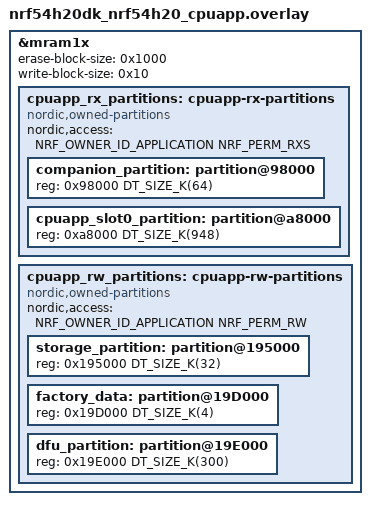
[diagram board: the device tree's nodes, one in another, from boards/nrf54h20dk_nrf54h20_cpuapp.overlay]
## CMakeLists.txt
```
#
# Copyright (c) 2023 Nordic Semiconductor ASA
#
# SPDX-License-Identifier: LicenseRef-Nordic-5-Clause
#

cmake_minimum_required(VERSION 3.20.0)

find_package(Zephyr HINTS $ENV{ZEPHYR_BASE})

project(matter-bridge)

# Enable GNU STD support and initialize the Matter Data Model.
include(${ZEPHYR_CONNECTEDHOMEIP_MODULE_DIR}/config/nrfconnect/app/enable-gnu-std.cmake)
include(${ZEPHYR_CONNECTEDHOMEIP_MODULE_DIR}/src/app/chip_data_model.cmake)

# NORDIC SDK APP START

# Include all source files that are located in the Matter common directory.
include(${ZEPHYR_NRF_MODULE_DIR}/samples/matter/common/cmake/source_common.cmake)

target_include_directories(app PRIVATE
    src
    src/bridged_device_types
    ${CONFIG_NCS_SAMPLE_MATTER_ZAP_FILES_PATH}
    ${ZEPHYR_NRF_MODULE_DIR}/samples/matter/common/src/bridge/
    ${ZEPHYR_NRF_MODULE_DIR}/samples/matter/common/src/bridge/util
)

target_sources(app PRIVATE
    src/app_task.cpp
    src/main.cpp
    src/bridge_shell.cpp
    src/zcl_callbacks.cpp
    ${ZEPHYR_NRF_MODULE_DIR}/samples/matter/common/src/bridge/bridge_manager.cpp
    ${ZEPHYR_NRF_MODULE_DIR}/samples/matter/common/src/bridge/matter_bridged_device.cpp
    ${ZEPHYR_NRF_MODULE_DIR}/samples/matter/common/src/bridge/bridge_storage_manager.cpp
    ${ZEPHYR_NRF_MODULE_DIR}/samples/matter/common/src/bridge/bridged_device_data_provider.cpp
    ${ZEPHYR_NRF_MODULE_DIR}/samples/matter/common/src/binding/binding_handler.cpp
)

if(CONFIG_BRIDGED_DEVICE_BT)
    target_sources(app PRIVATE
         ${ZEPHYR_NRF_MODULE_DIR}/samples/matter/common/src/bridge/ble_connectivity_manager.cpp
        src/ble_providers/ble_bridged_device_factory.cpp
    )
    target_include_directories(app PRIVATE src/ble_providers)

if(CONFIG_BRIDGE_ONOFF_LIGHT_BRIDGED_DEVICE AND (CONFIG_BRIDGE_GENERIC_SWITCH_BRIDGED_DEVICE OR CONFIG_BRIDGE_ONOFF_LIGHT_SWITCH_BRIDGED_DEVICE))
    target_sources(app PRIVATE
        src/bridged_device_types/onoff_light.cpp
        src/ble_providers/ble_lbs_data_provider.cpp
    )

if(CONFIG_BRIDGE_GENERIC_SWITCH_BRIDGED_DEVICE)
    target_sources(app PRIVATE src/bridged_device_types/generic_switch.cpp)
endif()

if(CONFIG_BRIDGE_ONOFF_LIGHT_SWITCH_BRIDGED_DEVICE)
    target_sources(app PRIVATE
        src/bridged_device_types/onoff_light_switch.cpp
    )
endif()

endif() # CONFIG_BRIDGE_ONOFF_LIGHT_BRIDGED_DEVICE AND (CONFIG_BRIDGE_GENERIC_SWITCH_BRIDGED_DEVICE OR CONFIG_BRIDGE_ONOFF_LIGHT_SWITCH_BRIDGED_DEVICE)

if(CONFIG_BRIDGE_HUMIDITY_SENSOR_BRIDGED_DEVICE)
    target_sources(app PRIVATE
        src/bridged_device_types/humidity_sensor.cpp
    )
endif() # CONFIG_BRIDGE_HUMIDITY_SENSOR_BRIDGED_DEVICE

if(CONFIG_BRIDGE_TEMPERATURE_SENSOR_BRIDGED_DEVICE)
    target_sources(app PRIVATE
        src/bridged_device_types/temperature_sensor.cpp
    )
endif() # CONFIG_BRIDGE_TEMPERATURE_SENSOR_BRIDGED_DEVICE

# Assume it makes no sense to support BLE environmental sensor without all Matter counterparts
if(CONFIG_BRIDGE_TEMPERATURE_SENSOR_BRIDGED_DEVICE AND CONFIG_BRIDGE_HUMIDITY_SENSOR_BRIDGED_DEVICE)
    target_sources(app PRIVATE
        src/ble_providers/ble_environmental_data_provider.cpp
    )
endif() # CONFIG_BRIDGE_TEMPERATURE_SENSOR_BRIDGED_DEVICE AND CONFIG_BRIDGE_HUMIDITY_SENSOR_BRIDGED_DEVICE

else()
    target_sources(app PRIVATE
        src/simulated_providers/simulated_bridged_device_factory.cpp
    )
    target_include_directories(app PRIVATE src/simulated_providers)

if(CONFIG_BRIDGE_ONOFF_LIGHT_BRIDGED_DEVICE AND (CONFIG_BRIDGE_GENERIC_SWITCH_BRIDGED_DEVICE OR CONFIG_BRIDGE_ONOFF_LIGHT_SWITCH_BRIDGED_DEVICE))
    target_sources(app PRIVATE
        src/bridged_device_types/onoff_light.cpp
        src/simulated_providers/simulated_onoff_light_data_provider.cpp
    )

if(CONFIG_BRIDGE_GENERIC_SWITCH_BRIDGED_DEVICE)
    target_sources(app PRIVATE
        src/bridged_device_types/generic_switch.cpp
        src/simulated_providers/simulated_generic_switch_data_provider.cpp
    )
endif()

if(CONFIG_BRIDGE_ONOFF_LIGHT_SWITCH_BRIDGED_DEVICE)
    target_sources(app PRIVATE
        src/bridged_device_types/onoff_light_switch.cpp
        src/simulated_providers/simulated_onoff_light_switch_data_provider.cpp
    )
endif()

endif() # CONFIG_BRIDGE_ONOFF_LIGHT_BRIDGED_DEVICE AND (CONFIG_BRIDGE_GENERIC_SWITCH_BRIDGED_DEVICE OR CONFIG_BRIDGE_ONOFF_LIGHT_SWITCH_BRIDGED_DEVICE))

if(CONFIG_BRIDGE_TEMPERATURE_SENSOR_BRIDGED_DEVICE)
    target_sources(app PRIVATE
            src/bridged_device_types/temperature_sensor.cpp
            src/simulated_providers/simulated_temperature_sensor_data_provider.cpp
    )
endif() # CONFIG_BRIDGE_TEMPERATURE_SENSOR_BRIDGED_DEVICE

if(CONFIG_BRIDGE_HUMIDITY_SENSOR_BRIDGED_DEVICE)
    target_sources(app PRIVATE
        src/bridged_device_types/humidity_sensor.cpp
        src/simulated_providers/simulated_humidity_sensor_data_provider.cpp
    )
endif() # CONFIG_BRIDGE_HUMIDITY_SENSOR_BRIDGED_DEVICE

endif() # CONFIG_BRIDGED_DEVICE_BT

chip_configure_data_model(app
    INCLUDE_SERVER
    BYPASS_IDL
    GEN_DIR ${CONFIG_NCS_SAMPLE_MATTER_ZAP_FILES_PATH}/zap-generated
    ZAP_FILE ${CMAKE_CURRENT_SOURCE_DIR}/${CONFIG_NCS_SAMPLE_MATTER_ZAP_FILES_PATH}/bridge.zap
)
# NORDIC SDK APP END
```

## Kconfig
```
#
# Copyright (c) 2023 Nordic Semiconductor
#
# SPDX-License-Identifier: LicenseRef-Nordic-5-Clause
#
mainmenu "Matter nRF Connect Bridge Example Application"

config BRIDGE_ONOFF_LIGHT_BRIDGED_DEVICE
	bool "Support for OnOff Light bridged device"
	default y

config BRIDGE_TEMPERATURE_SENSOR_BRIDGED_DEVICE
	bool "Support for Temperature Sensor bridged device"
	default y

config BRIDGE_HUMIDITY_SENSOR_BRIDGED_DEVICE
	bool "Support for Humidity Sensor bridged device"
	default y

choice BRIDGE_SWITCH_BRIDGED_DEVICE
	prompt "Bridged device switch implementation"
	default BRIDGE_GENERIC_SWITCH_BRIDGED_DEVICE

config BRIDGE_GENERIC_SWITCH_BRIDGED_DEVICE
	bool "Support for Generic Switch bridged device"

config BRIDGE_ONOFF_LIGHT_SWITCH_BRIDGED_DEVICE
	bool "Support for OnOff Light Switch bridged device"

endchoice

choice BRIDGED_DEVICE_IMPLEMENTATION
	prompt "Bridged Device implementation"
	default BRIDGED_DEVICE_SIMULATED

	config BRIDGED_DEVICE_SIMULATED
		bool "Simulated Bridged Device"
		help
		  Enables using simulated bridged devices that do not perform
		  real operations, but emulate exemplary data to imitate the real
		  device behavior.

	config BRIDGED_DEVICE_BT
		bool "Bluetooth LE Bridged Device"
		help
		  Enables using real bridged devices that communicate with the Matter bridge device
		  over Bluetooth LE.

endchoice

if BRIDGED_DEVICE_SIMULATED

choice BRIDGED_DEVICE_SIMULATED_ONOFF_IMPLEMENTATION
	prompt "Simulated bridged onoff device implementation"
	default BRIDGED_DEVICE_SIMULATED_ONOFF_SHELL

	config BRIDGED_DEVICE_SIMULATED_ONOFF_AUTOMATIC
		bool "Automatically simulated bridged onoff device"
		help
		  Enables using simulated bridged onoff device that
		  automatically changes its state periodically.

	config BRIDGED_DEVICE_SIMULATED_ONOFF_SHELL
		bool "Shell controlled simulated bridged onoff device"
		help
		  Enables using simulated bridged onoff device that is
		  controlled by shell commands.

endchoice

endif

if BRIDGED_DEVICE_BT

config BT_CENTRAL
	default y

config BT_SCAN
	default y

# Configure how many Bluetooth LE devices the Matter bridge can support (the final number is given value - 1, as 1 connection is used for the Matter Bluetooth LE service).
config BT_MAX_CONN
	default 10

# Set ACL RX count to CONFIG_BT_MAX_CONN + 1, as it is expected that CONFIG_BT_BUF_ACL_RX_COUNT > CONFIG_BT_MAX_CONN.
config BT_BUF_ACL_RX_COUNT
	default 11

config BT_SCAN_FILTER_ENABLE
	default y

# Configure how many Bluetooth LE service UUIDs the Matter bridge can scan.
config BT_SCAN_UUID_CNT
	default 2

config BT_SCAN_ADDRESS_CNT
	default 1

config BT_GATT_CLIENT
	default y

config BT_GATT_DM
	default y

config BT_EXT_ADV
	default y

config BT_SMP
	default y

if BT_SMP

config BT_SETTINGS
	default y

# Configure how many Bluetooth LE devices will be paired with Matter bridge. Assuming it will be only bridged devices, it should be set to BT_MAX_CONN - 1.
config BT_MAX_PAIRED
	default 9

# Use two Bluetooth LE identities. The first one is used by the peripheral for Matter service advertising purposes, and the other is used by the Matter bridge central.
config BT_ID_MAX
	default 2

config BT_EXT_ADV_LEGACY_SUPPORT
	default y

endif

config BRIDGE_BLE_DEVICE_POLLING_INTERVAL
	int "BLE humidity measurement readout polling interval in ms"
	default 3000

endif

if BRIDGE_TEMPERATURE_SENSOR_BRIDGED_DEVICE

config BRIDGE_TEMPERATURE_SENSOR_MIN_MEASURED_VALUE
	int "Default minimum measured value allowed by the bridged temperature sensor device"
	default -20

config BRIDGE_TEMPERATURE_SENSOR_MAX_MEASURED_VALUE
	int "Default maximum measured value allowed by the bridged temperature sensor device"
	default 60

endif

if BRIDGE_HUMIDITY_SENSOR_BRIDGED_DEVICE

config BRIDGE_HUMIDITY_SENSOR_MIN_MEASURED_VALUE
	int "Default minimum measured value allowed by the bridged humidity sensor device"
	default 0

config BRIDGE_HUMIDITY_SENSOR_MAX_MEASURED_VALUE
	int "Default maximum measured value allowed by the bridged humidity sensor device"
	default 100

endif

# Enable Read Client functionality for all build configurations.
config CHIP_ENABLE_READ_CLIENT
	default y

config NCS_SAMPLE_MATTER_PERSISTENT_STORAGE
	default y

config BRIDGE_SMART_PLUG_SUPPORT
	bool "Enables additional endpoint implementing Matter smart plug functionality"
	default n

# Sample configuration used for Thread networking
if NET_L2_OPENTHREAD

choice OPENTHREAD_NORDIC_LIBRARY_CONFIGURATION
	default OPENTHREAD_NORDIC_LIBRARY_FTD
endchoice

choice OPENTHREAD_DEVICE_TYPE
	default OPENTHREAD_FTD
endchoice

endif # NET_L2_OPENTHREAD

# Dummy Kconfig just to select experimental for some of the configurations.
config BRIDGE_EXPERIMENTAL
	bool
	default y if NET_L2_OPENTHREAD || BRIDGE_SMART_PLUG_SUPPORT
	select EXPERIMENTAL

source "${ZEPHYR_CONNECTEDHOMEIP_MODULE_DIR}/config/nrfconnect/chip-module/Kconfig.features"
source "${ZEPHYR_CONNECTEDHOMEIP_MODULE_DIR}/config/nrfconnect/chip-module/Kconfig.defaults"
source "${ZEPHYR_NRF_MODULE_DIR}/samples/matter/common/src/bridge/Kconfig"
source "${ZEPHYR_NRF_MODULE_DIR}/samples/matter/common/src/Kconfig"
source "Kconfig.zephyr"
```

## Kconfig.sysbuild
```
#
# Copyright (c) 2023 Nordic Semiconductor ASA
#
# SPDX-License-Identifier: LicenseRef-Nordic-5-Clause
#

config WIFI_NRF70
	default y if BOARD_NRF7002DK

#### Radio core
config NRF_DEFAULT_IPC_RADIO
	default y

# Enable Bluetooth serialization to network core
config NETCORE_IPC_RADIO_BT_HCI_IPC
	default y

#### Bootloader
choice BOOTLOADER
	default BOOTLOADER_MCUBOOT if !SOC_SERIES_NRF54HX
endchoice

# Enable IEEE802.15.4 serialization to network core
# This config automatically pulls in the `overlay-802154.conf` in the ipc_radio image
config NETCORE_IPC_RADIO_IEEE802154
	default y if (SOC_SERIES_NRF53X || SOC_SERIES_NRF54HX) && !WIFI_NRF70

if BOOTLOADER_MCUBOOT

#### DFU multi-image support
config DFU_MULTI_IMAGE_PACKAGE_BUILD
	default y

config DFU_MULTI_IMAGE_PACKAGE_APP
	default y

config PM_EXTERNAL_FLASH_MCUBOOT_SECONDARY
	default y

#### DFU network core configuration
if SOC_SERIES_NRF53X

config MCUBOOT_UPDATEABLE_IMAGES
	default 3 if (BOARD_NRF5340DK_NRF5340_CPUAPP && WIFI_NRF70) #### Support for WiFi patch on external flash memory.
	default 2

choice MCUBOOT_MODE
	default MCUBOOT_MODE_OVERWRITE_ONLY
endchoice

choice BOOT_SIGNATURE_TYPE
	default BOOT_SIGNATURE_TYPE_RSA
endchoice

config SECURE_BOOT_NETCORE
	default y

config NETCORE_APP_UPDATE
	default y

config DFU_MULTI_IMAGE_PACKAGE_NET
	default y

endif # SOC_SERIES_NRF53X
endif # BOOTLOADER_MCUBOOT

## Disable DFU for nRF54h20
config MATTER_OTA
	default n if SOC_SERIES_NRF54HX

#### Enable generating factory data
config MATTER_FACTORY_DATA_GENERATE
	default y

source "${ZEPHYR_BASE}/share/sysbuild/Kconfig"
```

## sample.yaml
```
sample:
  description: Matter Bridge
  name: Matter Bridge application
tests:
  applications.matter_bridge.release:
    sysbuild: true
    build_only: true
    extra_args: FILE_SUFFIX=release
      CONFIG_BRIDGE_GENERIC_SWITCH_BRIDGED_DEVICE=n
      CONFIG_BRIDGE_ONOFF_LIGHT_SWITCH_BRIDGED_DEVICE=y
    integration_platforms:
      - nrf7002dk/nrf5340/cpuapp
      - nrf5340dk/nrf5340/cpuapp
      - nrf54h20dk/nrf54h20/cpuapp
    platform_allow: nrf7002dk/nrf5340/cpuapp nrf5340dk/nrf5340/cpuapp
      nrf54h20dk/nrf54h20/cpuapp
    tags: sysbuild ci_applications_matter
  applications.matter_bridge.lto:
    sysbuild: true
    build_only: true
    extra_args: CONFIG_BRIDGE_GENERIC_SWITCH_BRIDGED_DEVICE=n
      CONFIG_BRIDGE_ONOFF_LIGHT_SWITCH_BRIDGED_DEVICE=y
    integration_platforms:
      - nrf7002dk/nrf5340/cpuapp
      - nrf5340dk/nrf5340/cpuapp
      - nrf54h20dk/nrf54h20/cpuapp
    platform_allow: nrf7002dk/nrf5340/cpuapp nrf5340dk/nrf5340/cpuapp
      nrf54h20dk/nrf54h20/cpuapp
    tags: sysbuild ci_applications_matter
  applications.matter_bridge.lto.br_ble:
    sysbuild: true
    build_only: true
    extra_args: CONFIG_BRIDGED_DEVICE_BT=y
      CONFIG_BRIDGE_GENERIC_SWITCH_BRIDGED_DEVICE=n
      CONFIG_BRIDGE_ONOFF_LIGHT_SWITCH_BRIDGED_DEVICE=y
    integration_platforms:
      - nrf7002dk/nrf5340/cpuapp
      - nrf5340dk/nrf5340/cpuapp
      - nrf54h20dk/nrf54h20/cpuapp
    platform_allow: nrf7002dk/nrf5340/cpuapp nrf5340dk/nrf5340/cpuapp
      nrf54h20dk/nrf54h20/cpuapp
    tags: sysbuild ci_applications_matter
  applications.matter_bridge.release.br_ble:
    sysbuild: true
    build_only: true
    extra_args: FILE_SUFFIX=release CONFIG_BRIDGED_DEVICE_BT=y
      CONFIG_BRIDGE_GENERIC_SWITCH_BRIDGED_DEVICE=n
      CONFIG_BRIDGE_ONOFF_LIGHT_SWITCH_BRIDGED_DEVICE=y
    integration_platforms:
      - nrf7002dk/nrf5340/cpuapp
      - nrf5340dk/nrf5340/cpuapp
      - nrf54h20dk/nrf54h20/cpuapp
    platform_allow: nrf7002dk/nrf5340/cpuapp nrf5340dk/nrf5340/cpuapp
      nrf54h20dk/nrf54h20/cpuapp
    tags: sysbuild ci_applications_matter
  applications.matter_bridge.lto.br_ble.smp_dfu:
    sysbuild: true
    build_only: true
    extra_args: CONFIG_CHIP_DFU_OVER_BT_SMP=y CONFIG_BRIDGED_DEVICE_BT=y
      CONFIG_BRIDGE_GENERIC_SWITCH_BRIDGED_DEVICE=n
      CONFIG_BRIDGE_ONOFF_LIGHT_SWITCH_BRIDGED_DEVICE=y
    integration_platforms:
      - nrf7002dk/nrf5340/cpuapp
    platform_allow: nrf7002dk/nrf5340/cpuapp
    tags: sysbuild ci_applications_matter
  applications.matter_bridge.lto.nrf5340.wifi:
    sysbuild: true
    build_only: true
    extra_args: matter_bridge_SHIELD=nrf7002ek SB_CONFIG_WIFI_PATCHES_EXT_FLASH_STORE=y
      mcuboot_CONFIG_UPDATEABLE_IMAGE_NUMBER=3 SB_CONFIG_WIFI_NRF70=y
      SB_CONFIG_DFU_MULTI_IMAGE_PACKAGE_WIFI_FW_PATCH=y
      CONFIG_CHIP_DFU_OVER_BT_SMP=y
      FILE_SUFFIX=nrf70ek
    integration_platforms:
      - nrf5340dk/nrf5340/cpuapp
    platform_allow: nrf5340dk/nrf5340/cpuapp
    tags: sysbuild ci_applications_matter
  applications.matter_bridge.lto.br_ble.nrf54h20.wifi:
    sysbuild: true
    build_only: true
    extra_args: SB_CONFIG_WIFI_NRF70=y CONFIG_CHIP_WIFI=y
      matter_bridge_SHIELD="nrf7002eb_interposer_p1;nrf7002eb" CONFIG_BRIDGED_DEVICE_BT=y
    integration_platforms:
      - nrf54h20dk/nrf54h20/cpuapp
    platform_allow: nrf54h20dk/nrf54h20/cpuapp
    tags: sysbuild ci_applications_matter
  applications.matter_bridge.release.br_ble.nrf54h20.wifi:
    sysbuild: true
    build_only: true
    extra_args: FILE_SUFFIX=release SB_CONFIG_WIFI_NRF70=y CONFIG_CHIP_WIFI=y
      matter_bridge_SHIELD="nrf7002eb_interposer_p1;nrf7002eb" CONFIG_BRIDGED_DEVICE_BT=y
    integration_platforms:
      - nrf54h20dk/nrf54h20/cpuapp
    platform_allow: nrf54h20dk/nrf54h20/cpuapp
    tags: sysbuild ci_applications_matter
  applications.matter_bridge.lto.br_ble.memory_profiling:
    sysbuild: true
    build_only: true
    extra_args: CONFIG_BRIDGE_GENERIC_SWITCH_BRIDGED_DEVICE=n
      CONFIG_BRIDGE_ONOFF_LIGHT_SWITCH_BRIDGED_DEVICE=y
      CONFIG_CHIP_MEMORY_PROFILING=y CONFIG_BRIDGED_DEVICE_BT=y
      CONFIG_BRIDGE_MIGRATE_VERSION_1=n
    integration_platforms:
      - nrf7002dk/nrf5340/cpuapp
      - nrf5340dk/nrf5340/cpuapp
      - nrf54h20dk/nrf54h20/cpuapp
    platform_allow: nrf7002dk/nrf5340/cpuapp nrf5340dk/nrf5340/cpuapp
      nrf54h20dk/nrf54h20/cpuapp
    tags: sysbuild ci_applications_matter
  applications.matter_bridge.lto.smart_plug:
    sysbuild: true
    build_only: true
    extra_args: matter_bridge_SNIPPET=onoff_plug
    integration_platforms:
      - nrf5340dk/nrf5340/cpuapp
    platform_allow: nrf5340dk/nrf5340/cpuapp
    tags: sysbuild ci_applications_matter
```

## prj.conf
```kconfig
#
# Copyright (c) 2023 Nordic Semiconductor ASA
#
# SPDX-License-Identifier: LicenseRef-Nordic-5-Clause
#

# This sample uses Kconfig.defaults to set options common for all
# samples. This file should contain only options specific for this sample
# or overrides of default values.

# Enable CHIP
CONFIG_CHIP=y
CONFIG_CHIP_PROJECT_CONFIG="src/chip_project_config.h"
# 32770 == 0x8002 (example bridge)
CONFIG_CHIP_DEVICE_PRODUCT_ID=32770
CONFIG_STD_CPP17=y

# Enable Matter pairing automatically on application start.
CONFIG_CHIP_ENABLE_PAIRING_AUTOSTART=y

# Enable Matter extended announcement and increase duration to 1 hour.
CONFIG_CHIP_BLE_EXT_ADVERTISING=y
CONFIG_CHIP_BLE_ADVERTISING_DURATION=60

# Add support for LEDs and buttons on Nordic development kits
CONFIG_DK_LIBRARY=y

# Bluetooth Low Energy configuration
CONFIG_BT_DEVICE_NAME="MatterBridge"

# Other settings
CONFIG_THREAD_NAME=y
CONFIG_MPU_STACK_GUARD=y
CONFIG_RESET_ON_FATAL_ERROR=n
CONFIG_CHIP_LIB_SHELL=y
CONFIG_NCS_SAMPLE_MATTER_TEST_SHELL=y

# Reduce assert verbosity to save flash space.
CONFIG_ASSERT_NO_FILE_INFO=y

# Disable NFC commissioning
CONFIG_CHIP_NFC_COMMISSIONING=n

# Reduce application size
CONFIG_USE_SEGGER_RTT=n

# Enable Factory Data feature
CONFIG_CHIP_FACTORY_DATA=y
CONFIG_CHIP_FACTORY_DATA_BUILD=y

# Enable LTO to decrease the flash usage.
CONFIG_LTO=y
CONFIG_ISR_TABLES_LOCAL_DECLARATION=y

# Increase heap size to accommodate the memory required for additional bridged devices.
CONFIG_CHIP_MALLOC_SYS_HEAP_SIZE=16384
```

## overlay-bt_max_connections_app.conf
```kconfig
#
# Copyright (c) 2023 Nordic Semiconductor ASA
#
# SPDX-License-Identifier: LicenseRef-Nordic-5-Clause
#

# Set 20 BLE connections, as it is an upper limit supported by the Soft Device Controller.
CONFIG_BT_MAX_CONN=20

# Set ACL RX count to CONFIG_BT_MAX_CONN + 1, as it is expected that CONFIG_BT_BUF_ACL_RX_COUNT > CONFIG_BT_MAX_CONN.
CONFIG_BT_BUF_ACL_RX_COUNT=21

# Set buffer sizes in a consistent way with the ones used by the network core.
CONFIG_BT_BUF_ACL_RX_SIZE=84
CONFIG_BT_BUF_ACL_TX_SIZE=84

# Set MTU size to fit in the single buffer and avoid fragmentation (BUF_SIZE = MTU_SIZE + 4 B of L2CAP header).
CONFIG_BT_L2CAP_TX_MTU=80

# Set max number of bridged BLE devices, which is CONFIG_BT_MAX_CONN-1, as 1 connection is reserved for Matter.
CONFIG_BRIDGE_MAX_BRIDGED_DEVICES_NUMBER=19
CONFIG_BT_MAX_PAIRED=19

# Assume that every bridged device uses only 1 endpoint, however it can be increased if specific use case requires it.
CONFIG_BRIDGE_MAX_DYNAMIC_ENDPOINTS_NUMBER=19
```

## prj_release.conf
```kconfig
#
# Copyright (c) 2023 Nordic Semiconductor ASA
#
# SPDX-License-Identifier: LicenseRef-Nordic-5-Clause
#

# This sample uses Kconfig.defaults to set options common for all
# samples. This file should contain only options specific for this sample
# or overrides of default values.

# Enable CHIP
CONFIG_CHIP=y
CONFIG_CHIP_PROJECT_CONFIG="src/chip_project_config.h"
# 32770 == 0x8002 (example bridge)
CONFIG_CHIP_DEVICE_PRODUCT_ID=32770
CONFIG_STD_CPP17=y

# Enable Matter pairing automatically on application start.
CONFIG_CHIP_ENABLE_PAIRING_AUTOSTART=y

# Enable Matter extended announcement and increase duration to 1 hour.
CONFIG_CHIP_BLE_EXT_ADVERTISING=y
CONFIG_CHIP_BLE_ADVERTISING_DURATION=60

# Add support for LEDs and buttons on Nordic development kits
CONFIG_DK_LIBRARY=y

# Bluetooth Low Energy configuration
CONFIG_BT_DEVICE_NAME="MatterBridge"

# Enable system reset on fatal error
CONFIG_RESET_ON_FATAL_ERROR=y

# Disable all debug features
CONFIG_USE_SEGGER_RTT=n
CONFIG_OPENTHREAD_SHELL=n
CONFIG_LOG=n
CONFIG_LOG_MODE_MINIMAL=n
CONFIG_ASSERT_VERBOSE=n
CONFIG_ASSERT_NO_FILE_INFO=y
CONFIG_PRINTK=n
CONFIG_PRINTK_SYNC=n
CONFIG_THREAD_NAME=n
CONFIG_BOOT_BANNER=n

# Disable NFC commissioning
CONFIG_CHIP_NFC_COMMISSIONING=n

# Enable Factory Data feature
CONFIG_CHIP_FACTORY_DATA=y
CONFIG_CHIP_FACTORY_DATA_BUILD=y

# Enable the Read Client for binding purposes
CONFIG_CHIP_ENABLE_READ_CLIENT=y

# Enable Watchdog
CONFIG_NCS_SAMPLE_MATTER_WATCHDOG=y

# Increase heap size to accommodate the memory required for additional bridged devices.
CONFIG_CHIP_MALLOC_SYS_HEAP_SIZE=16384
```

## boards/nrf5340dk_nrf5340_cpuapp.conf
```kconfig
#
# Copyright (c) 2023 Nordic Semiconductor ASA
#
# SPDX-License-Identifier: LicenseRef-Nordic-5-Clause
#

# Set 10 BLE connections, as it is an upper limit supported caused by RAM usage due to using Thread and BLE at same time.
CONFIG_BT_MAX_CONN=10

# Set ACL RX count to CONFIG_BT_MAX_CONN + 1, as it is expected that CONFIG_BT_BUF_ACL_RX_COUNT > CONFIG_BT_MAX_CONN.
CONFIG_BT_BUF_ACL_RX_COUNT=11

# Set buffer sizes in a consistent way with the ones used by the network core.
#id if oncomment it there is an error that rx buffer is out of range (minimal value is 69)
CONFIG_BT_BUF_ACL_RX_SIZE=69
CONFIG_BT_BUF_ACL_TX_SIZE=69

# Set MTU size to fit in the single buffer and avoid fragmentation (BUF_SIZE = MTU_SIZE + 4 B of L2CAP header).
CONFIG_BT_L2CAP_TX_MTU=65

# Set max number of bridged BLE devices, which is CONFIG_BT_MAX_CONN-1, as 1 connection is reserved for Matter.
CONFIG_BRIDGE_MAX_BRIDGED_DEVICES_NUMBER=9
CONFIG_BT_MAX_PAIRED=9

# Assume that every bridged device uses 2 endpoints, however it can be increased if specific use case requires it.
CONFIG_BRIDGE_MAX_DYNAMIC_ENDPOINTS_NUMBER=18
# 15.4 RX buffers were decreased to save RAM
CONFIG_NRF_802154_RX_BUFFERS=14
```

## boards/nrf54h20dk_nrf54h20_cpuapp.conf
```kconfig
#
# Copyright (c) 2024 Nordic Semiconductor ASA
#
# SPDX-License-Identifier: LicenseRef-Nordic-5-Clause
#

# TODO: Workaround to be removed once DFU and external flash will be supported on nRF54H20.
CONFIG_CHIP_QSPI_NOR=n

CONFIG_MPU_STACK_GUARD=n

# Enable PSA crypto from SSF client
CONFIG_PSA_SSF_CRYPTO_CLIENT=y
CONFIG_SSF_PSA_CRYPTO_SERVICE_ENABLED=y

# Disable Data Cache
CONFIG_DCACHE=n

# Set the ZMS sector count to match the settings partition size that is 32 kB for this application.
CONFIG_SETTINGS_ZMS_SECTOR_COUNT=8
# Workaround required as Zephyr L2 implies usage of NVS backend for settings.
# It should be removed once the proper fix will be applied in Zephyr.
CONFIG_NVS=n

# TODO: Enable factory data once it is available
CONFIG_CHIP_FACTORY_DATA=n

# TODO: Workaround to be removed once Zephyr's CONFIG_FPROTECT is supported on nRF54H20.
CONFIG_CHIP_FACTORY_DATA_WRITE_PROTECT=n

# Disable GPD
CONFIG_SOC_NRF54H20_GPD=n
```

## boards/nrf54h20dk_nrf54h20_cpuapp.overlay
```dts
/*
 * Copyright (c) 2024 Nordic Semiconductor ASA
 *
 * SPDX-License-Identifier: LicenseRef-Nordic-5-Clause
 */

// Base path of the following includes points to the nrf/include directory.
#include <../samples/matter/common/dts/nrf54h20/nrf54h20_cpuapp_peripherals.dtsi>
#include <../samples/matter/common/dts/nrf54h20/nrf54h20_cpuapp_memory_map.dtsi>
#include <../samples/matter/common/dts/nrf54h20/nrf54h20_ram_allocation.dtsi>

/delete-node/ &cpuapp_rx_partitions;
/delete-node/ &cpuapp_rw_partitions;

&mram1x {
	erase-block-size = <0x1000>;
	write-block-size = <0x10>;

	cpuapp_rx_partitions: cpuapp-rx-partitions {
		compatible = "nordic,owned-partitions", "fixed-partitions";
		status = "okay";
		nordic,access = <NRF_OWNER_ID_APPLICATION NRF_PERM_RXS>;
		#address-cells = <1>;
		#size-cells = <1>;

		companion_partition: partition@98000 {
			reg = <0x98000 DT_SIZE_K(64)>;
		};

		cpuapp_slot0_partition: partition@a8000 {
			reg = <0xa8000 DT_SIZE_K(948)>;
		};
	};

	cpuapp_rw_partitions: cpuapp-rw-partitions {
		compatible = "nordic,owned-partitions", "fixed-partitions";
		status = "okay";
		nordic,access = <NRF_OWNER_ID_APPLICATION NRF_PERM_RW>;
		#address-cells = <0x1>;
		#size-cells = <0x1>;

		storage_partition: partition@195000 {
			reg = <0x195000 DT_SIZE_K(32)>;
		};

		factory_data: partition@19D000 {
			reg = <0x19D000 DT_SIZE_K(4)>;
		};

		/* DFU partition to store SUIT manifests and Nordic Firmware update */
		dfu_partition: partition@19E000 {
			reg = <0x19E000 DT_SIZE_K(300)>;
		};
	};
};
```

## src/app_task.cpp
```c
/*
 * Copyright (c) 2023 Nordic Semiconductor ASA
 *
 * SPDX-License-Identifier: LicenseRef-Nordic-5-Clause
 */

#include "app_task.h"

#ifdef CONFIG_BRIDGED_DEVICE_BT
#include "ble_bridged_device_factory.h"
#else
#include "simulated_bridged_device_factory.h"
#endif /* CONFIG_BRIDGED_DEVICE_BT */

#include "app/matter_init.h"
#include "app/task_executor.h"
#include "board/board.h"
#include "bridge/bridge_manager.h"
#include "bridge/bridge_storage_manager.h"

#ifdef CONFIG_BRIDGED_DEVICE_BT
#include "bridge/ble_connectivity_manager.h"
#endif

#ifdef CONFIG_CHIP_OTA_REQUESTOR
#include "dfu/ota/ota_util.h"
#endif /* CONFIG_BRIDGED_DEVICE_BT */

#include <app-common/zap-generated/attributes/Accessors.h>
#include <app-common/zap-generated/ids/Attributes.h>
#include <app-common/zap-generated/ids/Clusters.h>
#include <app/server/OnboardingCodesUtil.h>

#ifdef CONFIG_BRIDGED_DEVICE_BT
#include <bluetooth/services/lbs.h>
#endif /* CONFIG_BRIDGED_DEVICE_BT */
#include <zephyr/logging/log.h>

#ifdef CONFIG_BRIDGE_SMART_PLUG_SUPPORT
#define APPLICATION_BUTTON_MASK DK_BTN2_MSK
#endif /* CONFIG_BRIDGE_SMART_PLUG_SUPPORT */

LOG_MODULE_DECLARE(app, CONFIG_CHIP_APP_LOG_LEVEL);

using namespace ::chip;
using namespace ::chip::app;
using namespace ::chip::DeviceLayer;
namespace
{

#ifdef CONFIG_BRIDGED_DEVICE_BT
static const bt_uuid *sUuidLbs = BT_UUID_LBS;
static const bt_uuid *sUuidEs = BT_UUID_ESS;
static const bt_uuid *sUuidServices[] = { sUuidLbs, sUuidEs };
static constexpr uint8_t kUuidServicesNumber = ARRAY_SIZE(sUuidServices);
/**
 * @brief Blink rates for indication the BLE Connectivity Manager state.
 *
 */
constexpr static uint32_t kPairingBlinkRate{ 100 };
constexpr static uint32_t kScanningBlinkRate_ms{ 300 };
constexpr static uint32_t kLostBlinkRate_ms{ 1000 };
#ifndef CONFIG_BRIDGE_SMART_PLUG_SUPPORT
void BLEStateChangeCallback(Nrf::BLEConnectivityManager::State state)
{
	switch (state) {
	case Nrf::BLEConnectivityManager::State::Connected:
		Nrf::PostTask([] { Nrf::GetBoard().GetLED(Nrf::DeviceLeds::LED2).Set(true); });
		break;
	case Nrf::BLEConnectivityManager::State::Scanning:
		Nrf::PostTask([] {
			Nrf::GetBoard()
				.GetLED(Nrf::DeviceLeds::LED2)
				.Blink(kScanningBlinkRate_ms, kScanningBlinkRate_ms);
		});
		break;
	case Nrf::BLEConnectivityManager::State::LostDevice:
		Nrf::PostTask([] {
			Nrf::GetBoard().GetLED(Nrf::DeviceLeds::LED2).Blink(kLostBlinkRate_ms, kLostBlinkRate_ms);
		});
		break;
	case Nrf::BLEConnectivityManager::State::Pairing:
		Nrf::PostTask([] {
			Nrf::GetBoard().GetLED(Nrf::DeviceLeds::LED2).Blink(kPairingBlinkRate, kPairingBlinkRate);
		});
		break;
	default:
		Nrf::PostTask([] { Nrf::GetBoard().GetLED(Nrf::DeviceLeds::LED2).Set(false); });
	}
}
#endif /* CONFIG_BRIDGE_SMART_PLUG_SUPPORT */

#endif /* CONFIG_BRIDGED_DEVICE_BT */

} /* namespace */

CHIP_ERROR AppTask::RestoreBridgedDevices()
{
	uint8_t count;
	uint8_t indexes[Nrf::BridgeManager::kMaxBridgedDevices] = { 0 };
	size_t indexesCount = 0;

	if (!Nrf::BridgeStorageManager::Instance().LoadBridgedDevicesCount(count)) {
		LOG_INF("No bridged devices to load from the storage.");
		return CHIP_NO_ERROR;
	}

	if (!Nrf::BridgeStorageManager::Instance().LoadBridgedDevicesIndexes(
		    indexes, Nrf::BridgeManager::kMaxBridgedDevices, indexesCount)) {
		return CHIP_NO_ERROR;
	}

	/* Load all devices based on the read count number. */
	for (size_t i = 0; i < indexesCount; i++) {
		Nrf::BridgeStorageManager::BridgedDevice device;
#ifdef CONFIG_BRIDGED_DEVICE_BT
		bt_addr_le_t btAddr;
		device.mUserData = reinterpret_cast<uint8_t *>(&btAddr);
		device.mUserDataSize = sizeof(btAddr);
#endif

		if (!Nrf::BridgeStorageManager::Instance().LoadBridgedDevice(device, indexes[i])) {
			return CHIP_ERROR_NOT_FOUND;
		}

		LOG_INF("Loaded bridged device on endpoint id %d from the storage", device.mEndpointId);

#ifdef CONFIG_BRIDGED_DEVICE_BT
		BleBridgedDeviceFactory::CreateDevice(device.mDeviceType, btAddr, device.mUniqueID, device.mNodeLabel,
						      indexes[i], device.mEndpointId);
#else
		SimulatedBridgedDeviceFactory::CreateDevice(device.mDeviceType, device.mUniqueID, device.mNodeLabel,
							    chip::Optional<uint8_t>(indexes[i]),
							    chip::Optional<uint16_t>(device.mEndpointId));
#endif
	}
	return CHIP_NO_ERROR;
}
#ifdef CONFIG_BRIDGE_SMART_PLUG_SUPPORT
void AppTask::SmartplugOnOffEventHandler()
{
	SystemLayer().ScheduleLambda([] {
		bool newState = !Nrf::GetBoard().GetLED(Nrf::DeviceLeds::LED2).GetState();
		Protocols::InteractionModel::Status status =
			Clusters::OnOff::Attributes::OnOff::Set(kSmartplugEndpointId, newState);
		if (status != Protocols::InteractionModel::Status::Success) {
			LOG_ERR("Updating on/off cluster failed: %x", to_underlying(status));
		}
	});
}

void AppTask::ButtonEventHandler(Nrf::ButtonState state, Nrf::ButtonMask hasChanged)
{
	if ((APPLICATION_BUTTON_MASK & hasChanged) & state) {
		Nrf::PostTask([] { SmartplugOnOffEventHandler(); });
	}
}
#endif /* CONFIG_BRIDGE_SMART_PLUG_SUPPORT */

CHIP_ERROR AppTask::Init()
{
	/* Initialize Matter stack */
	ReturnErrorOnFailure(Nrf::Matter::PrepareServer(Nrf::Matter::InitData{ .mPostServerInitClbk = [] {
#ifdef CONFIG_BRIDGED_DEVICE_BT
#ifndef CONFIG_BRIDGE_SMART_PLUG_SUPPORT
		Nrf::BLEConnectivityManager::Instance().RegisterStateCallback(BLEStateChangeCallback);
#endif /* CONFIG_BRIDGE_SMART_PLUG_SUPPORT */
		/* Initialize BLE Connectivity Manager before the Bridge Manager, as it must be ready to recover
		 * devices loaded from persistent storage during the bridge init. */
		CHIP_ERROR bleInitError =
			Nrf::BLEConnectivityManager::Instance().Init(sUuidServices, kUuidServicesNumber);
		if (bleInitError != CHIP_NO_ERROR) {
			LOG_ERR("BLEConnectivityManager initialization failed");
			return bleInitError;
		}
#endif

		/* Initialize bridge manager */
		CHIP_ERROR bridgeMgrInitError = Nrf::BridgeManager::Instance().Init(RestoreBridgedDevices);
		if (bridgeMgrInitError != CHIP_NO_ERROR) {
			LOG_ERR("BridgeManager initialization failed");
			return bridgeMgrInitError;
		}
		return CHIP_NO_ERROR;
	} }));
#ifdef CONFIG_BRIDGE_SMART_PLUG_SUPPORT
	/* onoff plug part add buttonEventHandler*/
	if (!Nrf::GetBoard().Init(ButtonEventHandler)) {
		LOG_ERR("User interface initialization failed.");
		return CHIP_ERROR_INCORRECT_STATE;
	}
#else
	if (!Nrf::GetBoard().Init()) {
		LOG_ERR("User interface initialization failed.");
		return CHIP_ERROR_INCORRECT_STATE;
	}
#endif
	/* Register Matter event handler that controls the connectivity status LED based on the captured Matter
	 * network state. */
	ReturnErrorOnFailure(Nrf::Matter::RegisterEventHandler(Nrf::Board::DefaultMatterEventHandler, 0));

	return Nrf::Matter::StartServer();
}

CHIP_ERROR AppTask::StartApp()
{
	ReturnErrorOnFailure(Init());

	while (true) {
		Nrf::DispatchNextTask();
	}

	return CHIP_NO_ERROR;
}
```
